VERSION ""

NS_ :

BS_:

BU_: Device Host

BO_ 2565865982 LVPSpnp_1s: 1 Vector__XXX
 SG_ val_bool : 0|1@1+ (1,0) [0|1] "" Vector__XXX

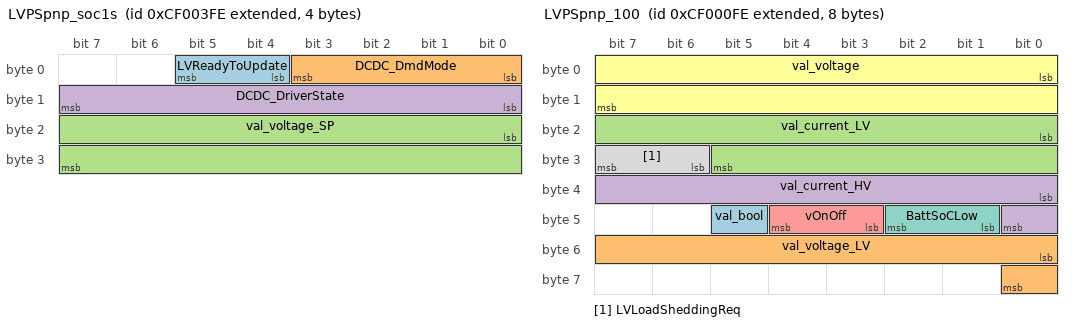
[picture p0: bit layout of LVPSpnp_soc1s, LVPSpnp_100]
BO_ 2364539902 LVPSpnp_soc1s: 4 Vector__XXX
 SG_ LVReadyToUpdate : 4|2@1+ (1,0) [0|3] "" Vector__XXX
 SG_ DCDC_DmdMode : 0|4@1+ (1,0) [0|15] "" Vector__XXX
 SG_ val_voltage_SP : 16|16@1+ (0.1,0) [0|6553.5] "V" Vector__XXX
 SG_ DCDC_DriverState : 8|8@1+ (1,0) [0|255] "" Vector__XXX

BO_ 2364539134 LVPSpnp_100: 8 Vector__XXX
 SG_ val_bool : 45|1@1+ (1,0) [0|1] "" Vector__XXX
 SG_ val_voltage_LV : 48|9@1+ (0.1,0) [0|51.1] "V" Vector__XXX
 SG_ val_current_LV : 16|14@1- (0.1,0) [-819.2|819.1] "A" Vector__XXX
 SG_ val_current_HV : 32|9@1- (0.1,0) [-25.6|25.5] "A" Vector__XXX
 SG_ vOnOff : 43|2@1+ (1,0) [0|0] "" Vector__XXX
 SG_ val_voltage : 0|16@1+ (0.001,0) [0|65.535] "V" Vector__XXX
 SG_ BattSoCLow : 41|2@1+ (1,0) [0|0] "" Vector__XXX
 SG_ LVLoadSheddingReq : 30|2@1+ (1,0) [0|3] "" Vector__XXX

BO_ 2364539646 LVPSpnp_soc100: 8 Vector__XXX
 SG_ val_current_lim : 0|16@1+ (1,0) [0|65535] "A" Vector__XXX

CM_ "Arrival Low Voltage System Database.
$DBC storage: //depot/auto/dbc/Software_Modules/LV_System/LV/ $
$Change: 0 $
$DateTime: 2020/11/18 22:30:00 $
$Revision: #1 $
$Author: lyamin@arrival.com $
Arrival LV Database";
CM_ BO_ 2565865982 "Message from LVC to IDD";
CM_ SG_ 2565865982 val_bool "Shutdown request for dcdc";
CM_ BO_ 2364539902 "Message with LV system states";
CM_ SG_ 2364539902 LVReadyToUpdate "Feedback that device ready for FW update";
CM_ SG_ 2364539902 DCDC_DmdMode "DCDC Converter Mode Demand";
CM_ SG_ 2364539902 val_voltage_SP "DCDC Converter voltage setpoint demand";
CM_ SG_ 2364539902 DCDC_DriverState "DCDC State reported by Meta DCDC Driver";
CM_ BO_ 2364539134 "Message with the 1st LV DCDC status information";
CM_ SG_ 2364539134 val_bool "Shutdown request for dcdc";
CM_ SG_ 2364539134 val_voltage_LV "DCDC output voltage";
CM_ SG_ 2364539134 val_current_LV "DCDC output current";
CM_ SG_ 2364539134 val_current_HV "DCDC input current";
CM_ BO_ 2364539646 "Message with LV system master commands to LV system slave";
CM_ SG_ 2364539646 val_current_lim "Current limit for DCDC";
BA_DEF_  "BusType" STRING ;
BA_DEF_  "DBName" STRING ;
BA_DEF_  "DatabaseVersion" STRING ;
BA_DEF_ BO_  "GenMsgCycleTime" INT 0 3600000;
BA_DEF_ BO_  "GenMsgDelayTime" INT 0 1000;
BA_DEF_ BO_  "GenMsgILSupport" ENUM  "No","Yes";
BA_DEF_ BO_  "GenMsgRequestable" INT 0 1;
BA_DEF_ BO_  "GenMsgSendType" ENUM  "cyclic","NotUsed","NotUsed","NotUsed","NotUsed","NotUsed","NotUsed","IfActive","noMsgSendType";
BA_DEF_ SG_  "GenSigEVName" STRING ;
BA_DEF_ SG_  "GenSigILSupport" ENUM  "No","Yes";
BA_DEF_ SG_  "GenSigSendType" ENUM  "Cyclic","OnWrite","OnWriteWithRepetition","OnChange","OnChangeWithRepetition","IfActive","IfActiveWithRepetition","NoSigSendType";
BA_DEF_ BU_  "NmStationAddress" INT 0 255;
BA_DEF_  "ProtocolType" STRING ;
BA_DEF_  "SAE_J1939_21_SpecVersion" STRING ;
BA_DEF_  "SAE_J1939_71_SpecVersion" STRING ;
BA_DEF_  "SAE_J1939_73_SpecVersion" STRING ;
BA_DEF_  "SAE_J1939_75_SpecVersion" STRING ;
BA_DEF_  "SAE_J1939_81_SpecVersion" STRING ;
BA_DEF_  "SAE_J1939_DA_SpecVersion" STRING ;
BA_DEF_ BO_  "SendOnChange" ENUM  "No","Yes";
BA_DEF_ SG_  "SigType" ENUM  "Default","Range","RangeSigned","ASCII","Discrete","Control","ReferencePGN","DTC","StringDelimiter","StringLength","StringLengthControl","MessageCounter","MessageChecksum";
BA_DEF_ BO_  "VFrameFormat" ENUM  "StandardCAN","ExtendedCAN","reserved","J1939PG","reserved","reserved","reserved","reserved","reserved","reserved","reserved","reserved","reserved","reserved","StandardCAN_FD","ExtendedCAN_FD";
BA_DEF_DEF_  "BusType" "";
BA_DEF_DEF_  "DBName" "";
BA_DEF_DEF_  "DatabaseVersion" "";
BA_DEF_DEF_  "GenMsgCycleTime" 0;
BA_DEF_DEF_  "GenMsgDelayTime" 0;
BA_DEF_DEF_  "GenMsgILSupport" "Yes";
BA_DEF_DEF_  "GenMsgRequestable" 1;
BA_DEF_DEF_  "GenMsgSendType" "noMsgSendType";
BA_DEF_DEF_  "GenSigEVName" "Env@Nodename_@Signame";
BA_DEF_DEF_  "GenSigILSupport" "Yes";
BA_DEF_DEF_  "GenSigSendType" "NoSigSendType";
BA_DEF_DEF_  "NmStationAddress" 254;
BA_DEF_DEF_  "ProtocolType" "";
BA_DEF_DEF_  "SAE_J1939_21_SpecVersion" "";
BA_DEF_DEF_  "SAE_J1939_71_SpecVersion" "";
BA_DEF_DEF_  "SAE_J1939_73_SpecVersion" "";
BA_DEF_DEF_  "SAE_J1939_75_SpecVersion" "";
BA_DEF_DEF_  "SAE_J1939_81_SpecVersion" "";
BA_DEF_DEF_  "SAE_J1939_DA_SpecVersion" "";
BA_DEF_DEF_  "SendOnChange" "No";
BA_DEF_DEF_  "SigType" "Default";
BA_DEF_DEF_  "VFrameFormat" "J1939PG";
BA_ "BusType" "CAN";
BA_ "DatabaseVersion" "1.0";
BA_ "ProtocolType" "J1939";
BA_ "SAE_J1939_21_SpecVersion" "2006-10";
BA_ "SAE_J1939_71_SpecVersion" "2012-10";
BA_ "SAE_J1939_73_SpecVersion" "2012-10";
BA_ "SAE_J1939_75_SpecVersion" "2012-05";
BA_ "SAE_J1939_81_SpecVersion" "2012-05";
BA_ "SAE_J1939_DA_SpecVersion" "2015-01";
BA_ "DBName" "LVPS_pnp";
BA_ "GenMsgSendType" BO_ 2565865982 0;
BA_ "GenMsgCycleTime" BO_ 2565865982 1000;
BA_ "GenMsgSendType" BO_ 2364539902 0;
BA_ "SendOnChange" BO_ 2364539902 1;
BA_ "GenMsgDelayTime" BO_ 2364539902 100;
BA_ "GenMsgCycleTime" BO_ 2364539902 1000;
BA_ "GenMsgSendType" BO_ 2364539134 0;
BA_ "GenMsgCycleTime" BO_ 2364539134 100;
BA_ "GenMsgCycleTime" BO_ 2364539646 100;
BA_ "GenMsgSendType" BO_ 2364539646 0;
BA_ "SendOnChange" BO_ 2364539646 1;
VAL_ 2364539902 LVReadyToUpdate 3 "NA" 2 "Error" 1 "Ready" 0 "NotReady" ;
VAL_ 2364539902 DCDC_DmdMode 7 "N/A" 6 "Discharge" 5 "Precharge" 4 "Reset" 3 "HVIL" 2 "Deactivation" 0 "Initialize" 1 "Activation" ;
VAL_ 2364539902 DCDC_DriverState 10 "DCDC reported fail state" 9 "Attempt to reset DCDC" 8 "LV system discharging" 7 "LV system precharging" 6 "Boost mode" 5 "Buck mode" 4 "HV interlock procedure" 3 "DCDC idling" 2 "Attempt to wake-up DCDC" 1 "Sending DCDC to sleep mode" 0 "DCDC state unknown" ;
VAL_ 2364539134 vOnOff 3 "Not Available" 2 "Error" 1 "On" 0 "Off" ;
VAL_ 2364539134 BattSoCLow 3 "Not_Available" 2 "SoC_Critically_Low_event" 1 "SoC_Low_event" 0 "No_SoC_Low_event" ;
VAL_ 2364539134 LVLoadSheddingReq 3 "Not_available" 2 "Critical_loads_only" 0 "No_load_inhibit" 1 "Primary_loads_only" ;
